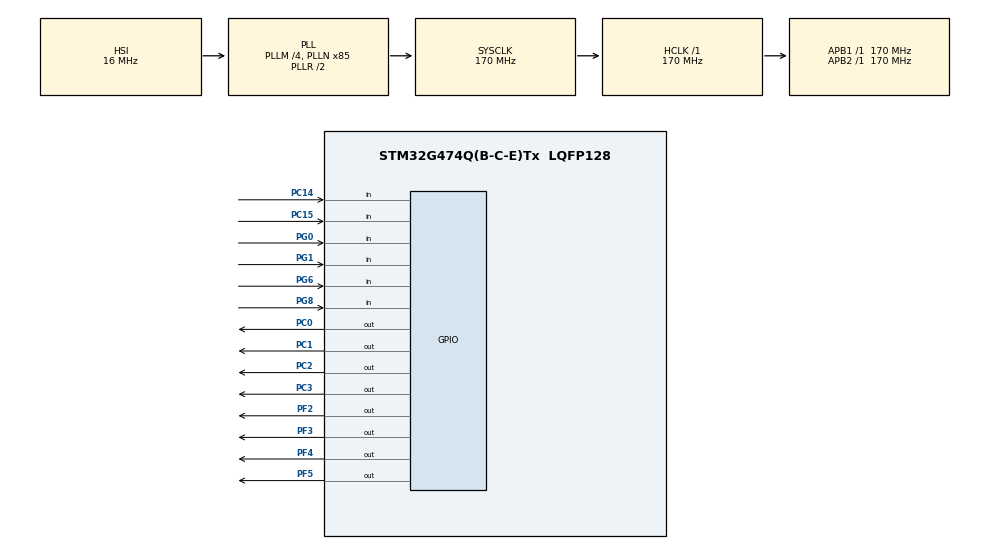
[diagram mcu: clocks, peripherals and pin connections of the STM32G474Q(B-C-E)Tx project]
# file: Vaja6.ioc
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Mcu.Family=STM32G4
Mcu.Name=STM32G474Q(B-C-E)Tx
Mcu.Package=LQFP128
NVIC.PriorityGroup=NVIC_PRIORITYGROUP_4
PC0.GPIO_PuPd=GPIO_NOPULL
PC0.Signal=GPIO_Output
PC1.Signal=GPIO_Output
PC14-OSC32_IN.GPIO_PuPd=GPIO_PULLUP
PC14-OSC32_IN.Signal=GPIO_Input
PC15-OSC32_OUT.GPIO_PuPd=GPIO_PULLUP
PC15-OSC32_OUT.Signal=GPIO_Input
PC2.Signal=GPIO_Output
PC3.Signal=GPIO_Output
PF2.Signal=GPIO_Output
PF3.Signal=GPIO_Output
PF4.Signal=GPIO_Output
PF5.Signal=GPIO_Output
PG0.GPIO_PuPd=GPIO_PULLUP
PG0.Signal=GPIO_Input
PG1.GPIO_PuPd=GPIO_PULLUP
PG1.Signal=GPIO_Input
PG6.GPIO_PuPd=GPIO_PULLUP
PG6.Signal=GPIO_Input
PG8.GPIO_PuPd=GPIO_PULLUP
PG8.Signal=GPIO_Input
ProjectManager.HeapSize=0x200
ProjectManager.StackSize=0x400
ProjectManager.TargetToolchain=STM32CubeIDE
RCC.ADC12Freq_Value=170000000
RCC.ADC345Freq_Value=170000000
RCC.AHBFreq_Value=170000000
RCC.APB1Freq_Value=170000000
RCC.APB1TimFreq_Value=170000000
RCC.APB2Freq_Value=170000000
RCC.APB2TimFreq_Value=170000000
RCC.CK48CLockSelection=RCC_USBCLKSOURCE_HSI48
RCC.CortexFreq_Value=170000000
RCC.EXTERNAL_CLOCK_VALUE=12288000
RCC.HCLKFreq_Value=170000000
RCC.HSE_VALUE=8000000
RCC.HSI48_VALUE=48000000
RCC.HSI_VALUE=16000000
RCC.LSE_VALUE=32768
RCC.PLLM=RCC_PLLM_DIV4
RCC.PLLN=85
RCC.SYSCLKFreq_VALUE=170000000
RCC.SYSCLKSource=RCC_SYSCLKSOURCE_PLLCLK
RCC.USBFreq_Value=48000000
RCC.VCOOutputFreq_Value=340000000
VP_SYS_VS_DBSignals.Mode=DisableDeadBatterySignals
board=custom

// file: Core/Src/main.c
/* USER CODE BEGIN Header */
/**
  ******************************************************************************
  * @file           : main.c
  * @brief          : Main program body
  ******************************************************************************
  * @attention
  *
  * Copyright (c) 2022 STMicroelectronics.
  * All rights reserved.
  *
  * This software is licensed under terms that can be found in the LICENSE file
  * in the root directory of this software component.
  * If no LICENSE file comes with this software, it is provided AS-IS.
  *
  ******************************************************************************
  */
/* USER CODE END Header */
#include "main.h"

void SystemClock_Config(void);
static void MX_GPIO_Init(void);

int main(void)
{

  /* MCU Configuration--------------------------------------------------------*/

  /* Reset of all peripherals, Initializes the Flash interface and the Systick. */
  HAL_Init();

  /* Configure the system clock */
  SystemClock_Config();

  /* Initialize all configured peripherals */
  MX_GPIO_Init();

  /* Infinite loop */
  /* USER CODE BEGIN WHILE */

  LED_init();
  //LED_demo();

  KBD_init();

  LEDs_on(0b10101010);
  HAL_Delay(500);
  LEDs_off(LEDs_read());
  LEDs_on(0b01010101);
  HAL_Delay(500);
  LEDs_off(LEDs_read());
  LEDs_on(0b10101010);
  HAL_Delay(500);
  LEDs_write(0);

  while (1)
  {
    /* USER CODE END WHILE */
	  //KBD_demo();

	  KBD_demo();

  }
}

void SystemClock_Config(void)
{
  RCC_OscInitTypeDef RCC_OscInitStruct = {0};
  RCC_ClkInitTypeDef RCC_ClkInitStruct = {0};

  /** Configure the main internal regulator output voltage
  */
  HAL_PWREx_ControlVoltageScaling(PWR_REGULATOR_VOLTAGE_SCALE1_BOOST);
  /** Initializes the RCC Oscillators according to the specified parameters
  * in the RCC_OscInitTypeDef structure.
  */
  RCC_OscInitStruct.OscillatorType = RCC_OSCILLATORTYPE_HSI;
  RCC_OscInitStruct.HSIState = RCC_HSI_ON;
  RCC_OscInitStruct.HSICalibrationValue = RCC_HSICALIBRATION_DEFAULT;
  RCC_OscInitStruct.PLL.PLLState = RCC_PLL_ON;
  RCC_OscInitStruct.PLL.PLLSource = RCC_PLLSOURCE_HSI;
  RCC_OscInitStruct.PLL.PLLM = RCC_PLLM_DIV4;
  RCC_OscInitStruct.PLL.PLLN = 85;
  RCC_OscInitStruct.PLL.PLLP = RCC_PLLP_DIV2;
  RCC_OscInitStruct.PLL.PLLQ = RCC_PLLQ_DIV2;
  RCC_OscInitStruct.PLL.PLLR = RCC_PLLR_DIV2;
  if (HAL_RCC_OscConfig(&RCC_OscInitStruct) != HAL_OK)
  {
    Error_Handler();
  }
  /** Initializes the CPU, AHB and APB buses clocks
  */
  RCC_ClkInitStruct.ClockType = RCC_CLOCKTYPE_HCLK|RCC_CLOCKTYPE_SYSCLK
                              |RCC_CLOCKTYPE_PCLK1|RCC_CLOCKTYPE_PCLK2;
  RCC_ClkInitStruct.SYSCLKSource = RCC_SYSCLKSOURCE_PLLCLK;
  RCC_ClkInitStruct.AHBCLKDivider = RCC_SYSCLK_DIV1;
  RCC_ClkInitStruct.APB1CLKDivider = RCC_HCLK_DIV1;
  RCC_ClkInitStruct.APB2CLKDivider = RCC_HCLK_DIV1;

  if (HAL_RCC_ClockConfig(&RCC_ClkInitStruct, FLASH_LATENCY_4) != HAL_OK)
  {
    Error_Handler();
  }
}

static void MX_GPIO_Init(void)
{
  LL_GPIO_InitTypeDef GPIO_InitStruct = {0};

  /* GPIO Ports Clock Enable */
  LL_AHB2_GRP1_EnableClock(LL_AHB2_GRP1_PERIPH_GPIOC);
  LL_AHB2_GRP1_EnableClock(LL_AHB2_GRP1_PERIPH_GPIOF);
  LL_AHB2_GRP1_EnableClock(LL_AHB2_GRP1_PERIPH_GPIOG);

  /**/
  LL_GPIO_ResetOutputPin(GPIOF, LL_GPIO_PIN_3);

  /**/
  LL_GPIO_ResetOutputPin(GPIOF, LL_GPIO_PIN_4);

  /**/
  LL_GPIO_ResetOutputPin(GPIOF, LL_GPIO_PIN_5);

  /**/
  LL_GPIO_ResetOutputPin(GPIOC, LL_GPIO_PIN_0);

  /**/
  LL_GPIO_ResetOutputPin(GPIOC, LL_GPIO_PIN_1);

  /**/
  LL_GPIO_ResetOutputPin(GPIOC, LL_GPIO_PIN_2);

  /**/
  LL_GPIO_ResetOutputPin(GPIOC, LL_GPIO_PIN_3);

  /**/
  LL_GPIO_ResetOutputPin(GPIOF, LL_GPIO_PIN_2);

  /**/
  GPIO_InitStruct.Pin = LL_GPIO_PIN_14;
  GPIO_InitStruct.Mode = LL_GPIO_MODE_INPUT;
  GPIO_InitStruct.Pull = LL_GPIO_PULL_UP;
  LL_GPIO_Init(GPIOC, &GPIO_InitStruct);

  /**/
  GPIO_InitStruct.Pin = LL_GPIO_PIN_15;
  GPIO_InitStruct.Mode = LL_GPIO_MODE_INPUT;
  GPIO_InitStruct.Pull = LL_GPIO_PULL_UP;
  LL_GPIO_Init(GPIOC, &GPIO_InitStruct);

  /**/
  GPIO_InitStruct.Pin = LL_GPIO_PIN_3;
  GPIO_InitStruct.Mode = LL_GPIO_MODE_OUTPUT;
  GPIO_InitStruct.Speed = LL_GPIO_SPEED_FREQ_LOW;
  GPIO_InitStruct.OutputType = LL_GPIO_OUTPUT_PUSHPULL;
  GPIO_InitStruct.Pull = LL_GPIO_PULL_NO;
  LL_GPIO_Init(GPIOF, &GPIO_InitStruct);

  /**/
  GPIO_InitStruct.Pin = LL_GPIO_PIN_4;
  GPIO_InitStruct.Mode = LL_GPIO_MODE_OUTPUT;
  GPIO_InitStruct.Speed = LL_GPIO_SPEED_FREQ_LOW;
  GPIO_InitStruct.OutputType = LL_GPIO_OUTPUT_PUSHPULL;
  GPIO_InitStruct.Pull = LL_GPIO_PULL_NO;
  LL_GPIO_Init(GPIOF, &GPIO_InitStruct);

  /**/
  GPIO_InitStruct.Pin = LL_GPIO_PIN_5;
  GPIO_InitStruct.Mode = LL_GPIO_MODE_OUTPUT;
  GPIO_InitStruct.Speed = LL_GPIO_SPEED_FREQ_LOW;
  GPIO_InitStruct.OutputType = LL_GPIO_OUTPUT_PUSHPULL;
  GPIO_InitStruct.Pull = LL_GPIO_PULL_NO;
  LL_GPIO_Init(GPIOF, &GPIO_InitStruct);

  /**/
  GPIO_InitStruct.Pin = LL_GPIO_PIN_0;
  GPIO_InitStruct.Mode = LL_GPIO_MODE_OUTPUT;
  GPIO_InitStruct.Speed = LL_GPIO_SPEED_FREQ_LOW;
  GPIO_InitStruct.OutputType = LL_GPIO_OUTPUT_PUSHPULL;
  GPIO_InitStruct.Pull = LL_GPIO_PULL_NO;
  LL_GPIO_Init(GPIOC, &GPIO_InitStruct);

  /**/
  GPIO_InitStruct.Pin = LL_GPIO_PIN_1;
  GPIO_InitStruct.Mode = LL_GPIO_MODE_OUTPUT;
  GPIO_InitStruct.Speed = LL_GPIO_SPEED_FREQ_LOW;
  GPIO_InitStruct.OutputType = LL_GPIO_OUTPUT_PUSHPULL;
  GPIO_InitStruct.Pull = LL_GPIO_PULL_NO;
  LL_GPIO_Init(GPIOC, &GPIO_InitStruct);

  /**/
  GPIO_InitStruct.Pin = LL_GPIO_PIN_2;
  GPIO_InitStruct.Mode = LL_GPIO_MODE_OUTPUT;
  GPIO_InitStruct.Speed = LL_GPIO_SPEED_FREQ_LOW;
  GPIO_InitStruct.OutputType = LL_GPIO_OUTPUT_PUSHPULL;
  GPIO_InitStruct.Pull = LL_GPIO_PULL_NO;
  LL_GPIO_Init(GPIOC, &GPIO_InitStruct);

  /**/
  GPIO_InitStruct.Pin = LL_GPIO_PIN_3;
  GPIO_InitStruct.Mode = LL_GPIO_MODE_OUTPUT;
  GPIO_InitStruct.Speed = LL_GPIO_SPEED_FREQ_LOW;
  GPIO_InitStruct.OutputType = LL_GPIO_OUTPUT_PUSHPULL;
  GPIO_InitStruct.Pull = LL_GPIO_PULL_NO;
  LL_GPIO_Init(GPIOC, &GPIO_InitStruct);

  /**/
  GPIO_InitStruct.Pin = LL_GPIO_PIN_2;
  GPIO_InitStruct.Mode = LL_GPIO_MODE_OUTPUT;
  GPIO_InitStruct.Speed = LL_GPIO_SPEED_FREQ_LOW;
  GPIO_InitStruct.OutputType = LL_GPIO_OUTPUT_PUSHPULL;
  GPIO_InitStruct.Pull = LL_GPIO_PULL_NO;
  LL_GPIO_Init(GPIOF, &GPIO_InitStruct);

  /**/
  GPIO_InitStruct.Pin = LL_GPIO_PIN_0;
  GPIO_InitStruct.Mode = LL_GPIO_MODE_INPUT;
  GPIO_InitStruct.Pull = LL_GPIO_PULL_UP;
  LL_GPIO_Init(GPIOG, &GPIO_InitStruct);

  /**/
  GPIO_InitStruct.Pin = LL_GPIO_PIN_1;
  GPIO_InitStruct.Mode = LL_GPIO_MODE_INPUT;
  GPIO_InitStruct.Pull = LL_GPIO_PULL_UP;
  LL_GPIO_Init(GPIOG, &GPIO_InitStruct);

  /**/
  GPIO_InitStruct.Pin = LL_GPIO_PIN_6;
  GPIO_InitStruct.Mode = LL_GPIO_MODE_INPUT;
  GPIO_InitStruct.Pull = LL_GPIO_PULL_UP;
  LL_GPIO_Init(GPIOG, &GPIO_InitStruct);

  /**/
  GPIO_InitStruct.Pin = LL_GPIO_PIN_8;
  GPIO_InitStruct.Mode = LL_GPIO_MODE_INPUT;
  GPIO_InitStruct.Pull = LL_GPIO_PULL_UP;
  LL_GPIO_Init(GPIOG, &GPIO_InitStruct);

}

void Error_Handler(void)
{
  __disable_irq();
  while (1)
  {
  }
}
